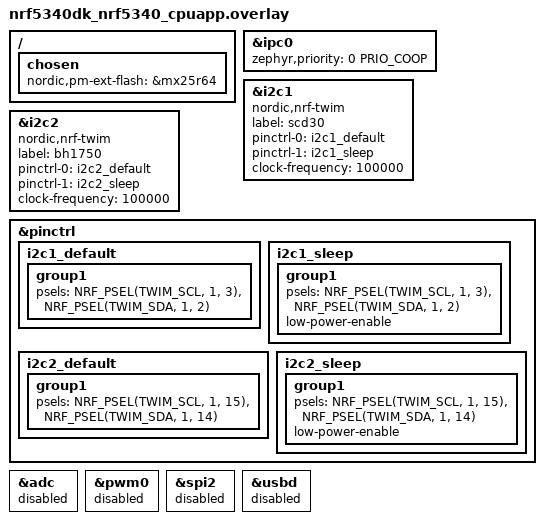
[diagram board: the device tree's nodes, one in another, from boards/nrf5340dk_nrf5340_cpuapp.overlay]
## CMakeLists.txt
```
#
# Copyright (c) 2021 Nordic Semiconductor ASA
#
# SPDX-License-Identifier: LicenseRef-Nordic-5-Clause
#

cmake_minimum_required(VERSION 3.20.0)

get_filename_component(MATTER_MODULE_ROOT $ENV{ZEPHYR_BASE}/../modules/lib/matter REALPATH)

# Set Kconfig root files that will be processed as a first Kconfig for used child images.
set(mcuboot_KCONFIG_ROOT ${MATTER_MODULE_ROOT}/config/nrfconnect/chip-module/Kconfig.mcuboot.root)
set(multiprotocol_rpmsg_KCONFIG_ROOT ${MATTER_MODULE_ROOT}/config/nrfconnect/chip-module/Kconfig.multiprotocol_rpmsg.root)
set(hci_rpmsg_KCONFIG_ROOT ${MATTER_MODULE_ROOT}/config/nrfconnect/chip-module/Kconfig.hci_rpmsg.root)

# For prj.conf the CONF_FILE is empty. In other case extract the exact file name from the path string.
if(CONF_FILE)
    get_filename_component(CONFIG_FILE_NAME ${CONF_FILE} NAME)
endif()

if(NOT CONFIG_FILE_NAME STREQUAL "prj_no_dfu.conf")
    set(PM_STATIC_YML_FILE ${CMAKE_CURRENT_SOURCE_DIR}/configuration/${BOARD}/pm_static_dfu.yml)
endif()

find_package(Zephyr HINTS $ENV{ZEPHYR_BASE})

project(matter-nrf-sensor-test)

set(COMMON_ROOT ${ZEPHYR_NRF_MODULE_DIR}/samples/matter/common)
set(NLIO_ROOT ${MATTER_MODULE_ROOT}/third_party/nlio/repo)
include(${MATTER_MODULE_ROOT}/config/nrfconnect/app/enable-gnu-std.cmake)
include(${MATTER_MODULE_ROOT}/src/app/chip_data_model.cmake)

# NORDIC SDK APP START
target_include_directories(app PRIVATE
    src
    ${COMMON_ROOT}/src
    ${NLIO_ROOT}/include
    ${MATTER_MODULE_ROOT}/zzz_generated/app-common
)

target_sources(app PRIVATE
    src/app_task.cpp
    src/app_driver.cpp
    src/main.cpp
    src/zcl_callbacks.cpp
    src/zap-generated/IMClusterCommandHandler.cpp
    src/zap-generated/callback-stub.cpp
    ${COMMON_ROOT}/src/led_widget.cpp
    $<$<BOOL:${CONFIG_NET_L2_OPENTHREAD}>:${COMMON_ROOT}/src/thread_util.cpp>
)

if(CONFIG_CHIP_OTA_REQUESTOR)
    target_sources(app PRIVATE ${COMMON_ROOT}/src/ota_util.cpp)
endif()

chip_configure_data_model(app
    INCLUDE_SERVER
    ZAP_FILE ${CMAKE_CURRENT_SOURCE_DIR}/src/template.zap
)
# NORDIC SDK APP END
```

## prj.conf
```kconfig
#
# Copyright (c) 2021 Nordic Semiconductor ASA
#
# SPDX-License-Identifier: LicenseRef-Nordic-5-Clause
#

# This sample uses Kconfig.defaults to set options common for all
# samples. This file should contain only options specific for this sample
# or overrides of default values.

# Enable CHIP
CONFIG_CHIP=y
CONFIG_CHIP_ENABLE_PAIRING_AUTOSTART=y
CONFIG_CHIP_PROJECT_CONFIG="src/chip_project_config.h"
# 32768 == 0x8000 (example Product ID added temporaly,
# but it must be changed with proper PID from the list:
# https://github.com/project-chip/connectedhomeip/blob/482e6fd03196a6de45465a90003947ef4b86e0b1/docs/examples/discussion/PID_allocation_for_example_apps.md)
CONFIG_CHIP_DEVICE_PRODUCT_ID=32768
CONFIG_STD_CPP14=y

# Add support for LEDs and buttons on Nordic development kits
CONFIG_DK_LIBRARY=y

# Bluetooth Low Energy configuration
CONFIG_BT_DEVICE_NAME="MatterTemplate"

# Other settings
CONFIG_THREAD_NAME=y
CONFIG_MPU_STACK_GUARD=y
CONFIG_RESET_ON_FATAL_ERROR=n

# Disable NFC commissioning
CONFIG_CHIP_NFC_COMMISSIONING=n

CONFIG_GPIO=y

CONFIG_GPIO_GET_CONFIG=y

#CONFIG_MAIN_STACK_SIZE=4096

# Stacks and heaps
CONFIG_MAIN_STACK_SIZE=16384
CONFIG_HEAP_MEM_POOL_SIZE=16384

# I2C
CONFIG_I2C=y
CONFIG_NRFX_TWIM1=y


# Rebooot
CONFIG_REBOOT=n
CONFIG_RESET_ON_FATAL_ERROR=n
```

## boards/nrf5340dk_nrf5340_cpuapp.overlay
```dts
/*
 * Copyright (c) 2021 Nordic Semiconductor ASA
 *
 * SPDX-License-Identifier: LicenseRef-Nordic-5-Clause
 */

#include <zephyr/dt-bindings/ipc_service/static_vrings.h>

/ {
	chosen {
		nordic,pm-ext-flash = &mx25r64;
	};
};

&ipc0 {
    zephyr,priority = <0 PRIO_COOP>;
};
&i2c1 {
	status = "okay";
	compatible = "nordic,nrf-twim";
	label = "scd30";
	pinctrl-0 = <&i2c1_default>;
	pinctrl-1 = <&i2c1_sleep>;
	pinctrl-names = "default", "sleep";
	clock-frequency = <100000>; 
};

&i2c2 {
	status = "okay";
	compatible = "nordic,nrf-twim";
	label = "bh1750";
	pinctrl-0 = <&i2c2_default>;
	pinctrl-1 = <&i2c2_sleep>;
	pinctrl-names = "default", "sleep";
	clock-frequency = <100000>; 
};

&pinctrl {
	i2c1_default: i2c1_default{
		group1 {
			psels = <NRF_PSEL(TWIM_SCL, 1, 3)>,
				<NRF_PSEL(TWIM_SDA, 1, 2)>;
		};
	};

	i2c1_sleep: i2c1_sleep{
		group1 {
			psels = <NRF_PSEL(TWIM_SCL, 1, 3)>,
					<NRF_PSEL(TWIM_SDA, 1, 2)>;
			low-power-enable;
		};
	};
	
	i2c2_default: i2c2_default{
		group1 {
			psels = <NRF_PSEL(TWIM_SCL, 1, 15)>,
					<NRF_PSEL(TWIM_SDA, 1, 14)>;
		};
	};

	i2c2_sleep: i2c2_sleep{
		group1 {
			psels = <NRF_PSEL(TWIM_SCL, 1, 15)>,
					<NRF_PSEL(TWIM_SDA, 1, 14)>;
			low-power-enable;
		};
	};
};

/* Disable unused peripherals to reduce power consumption */
&adc {
	status = "disabled";
};
&pwm0 {
	status = "disabled";
};
&spi2 {
	status = "disabled";
};
&usbd {
	status = "disabled";
};
```

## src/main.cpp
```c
/*
 * Copyright (c) 2021 Nordic Semiconductor ASA
 *
 * SPDX-License-Identifier: LicenseRef-Nordic-5-Clause
 */

#include "app_task.h"

#include <zephyr/logging/log.h>


int main()
{
	CHIP_ERROR err = AppTask::Instance().StartApp();

	LOG_ERR("Exited with code %" CHIP_ERROR_FORMAT, err.Format());
	return err == CHIP_NO_ERROR ? EXIT_SUCCESS : EXIT_FAILURE;
}
```

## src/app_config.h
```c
/*
 * Copyright (c) 2022 Nordic Semiconductor ASA
 *
 * SPDX-License-Identifier: LicenseRef-Nordic-5-Clause
 */

#pragma once

/* ---- Template App Config ---- */

#include "board_util.h"

#include <zephyr/kernel.h>
#include <zephyr/drivers/gpio.h>

#define LIGHTING_BUTTON DK_BTN1
#define LIGHTING_BUTTON_MASK DK_BTN1_MSK

#define SYSTEM_STATE_LED DK_LED2
//#define FACTORY_RESET_SIGNAL_LED DK_LED2

/* The devicetree node identifier for the "led0" alias. */
#define LED0_NODE DT_ALIAS(led0)


static constexpr struct gpio_dt_spec led = GPIO_DT_SPEC_GET(LED0_NODE, gpios);
```

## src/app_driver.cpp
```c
/**
 * @file app_driver.cpp
 * @author your name (you@domain.com)
 * @brief 
 * @version 0.1
 * @date 2023-02-24
 * 
 * @copyright Copyright (c) 2021, Sensirion AG
 * Copyright (c) 2021 Ruslan V. Uss <unclerus@gmail.com>
 * Copyright (c) 2021 Nate Usher <n.usher87@gmail.com>
 * 
 * Redistribution and use in source and binary forms, with or without
 * modification, are permitted provided that the following conditions are met:
 *
 * 1. Redistributions of source code must retain the above copyright notice,
 *    this list of conditions and the following disclaimer.
 * 2. Redistributions in binary form must reproduce the above copyright notice,
 *    this list of conditions and the following disclaimer in the documentation
 *    and/or other materials provided with the distribution.
 * 3. Neither the name of the copyright holder nor the names of itscontributors
 *    may be used to endorse or promote products derived from this software without
 *    specific prior written permission.
 *
 * THIS SOFTWARE IS PROVIDED BY THE COPYRIGHT HOLDERS AND CONTRIBUTORS "AS IS"
 * AND ANY EXPRESS OR IMPLIED WARRANTIES, INCLUDING, BUT NOT LIMITED TO, THE
 * IMPLIED WARRANTIES OF MERCHANTABILITY AND FITNESS FOR A PARTICULAR PURPOSE ARE
 * DISCLAIMED. IN NO EVENT SHALL THE COPYRIGHT HOLDER OR CONTRIBUTORS BE LIABLE
 * FOR ANY DIRECT, INDIRECT, INCIDENTAL, SPECIAL, EXEMPLARY, OR CONSEQUENTIAL
 * DAMAGES (INCLUDING, BUT NOT LIMITED TO, PROCUREMENT OF SUBSTITUTE GOODS OR
 * SERVICES; LOSS OF USE, DATA, OR PROFITS; OR BUSINESS INTERRUPTION) HOWEVER
 * CAUSED AND ON ANY THEORY OF LIABILITY, WHETHER IN CONTRACT, STRICT LIABILITY,
 * OR TORT (INCLUDING NEGLIGENCE OR OTHERWISE) ARISING IN ANY WAY OUT OF THE USE
 * OF THIS SOFTWARE, EVEN IF ADVISED OF THE POSSIBILITY OF SUCH DAMAGE.
 */

#include "app_driver.h"

#include <zephyr/kernel.h>
#include <zephyr/drivers/i2c.h>
#include <zephyr/device.h>
#include <zephyr/logging/log.h>

/**
 * @brief BH1750 I2C Device driver class. Suitable for reading lux values when requested. 
 * 
 * @param name I2C device name, as listed in i2c board overlay
 */
BH1750Driver::BH1750Driver(const std::string name)
    : spec{
        .bus = device_get_binding(name.c_str()), 
        .addr = I2C_ADDR
    }
{   
    // Get I2C device
    if (spec.bus == NULL)
    {
        LOG_ERR("Failed to get I2C device");
    } else
    {
        LOG_INF("Binded to device %s", spec.bus->name);
    }

    if (spec.addr != I2C_ADDR) {
        LOG_ERR("Address not set properly");
    }

    LOG_INF("[BH1750] Bus name: %s. Device addr: %d", spec.bus->name, spec.addr);
}

/**
 * @brief Initialize and configure i2c device. Set I2C speed to standard and write an initialization command
 * 
 * @param init_command (uint8_t *) 
 * @param buf_size 
 * 
 * @retval 0 If successful.
 * @retval -EIO General input / output error.
 */
int BH1750Driver::init()
{

    i2c_configure(spec.bus, I2C_SPEED_SET(I2C_SPEED_STANDARD));
    LOG_INF("Value of NRF_TWIM2_->PSEL.SCL : %d",NRF_TWIM2->PSEL.SCL);
    LOG_INF("Value of NRF_TWIM2->PSEL.SDA : %d",NRF_TWIM2->PSEL.SDA);
    LOG_INF("Value of NRF_TWIM2->FREQUENCY: %d",NRF_TWIM2->FREQUENCY);
    LOG_INF("26738688 -> 100k");

    uint8_t init_command[] = { CMD_TRIGGER_MEASUREMENT_MODE };

    CHECK(i2c_write_dt(&spec, init_command, 1), "I2C: Error in i2c_write transfer");
    return 0;
}

/**
 * @brief Read a value from the BH1750 device, convert to lux, and return.
 * 
 * @param lux (uint16_t *) [out] 
 * 
 * @retval 0 If successful.
 * @retval -EIO General input / output error.
 */
int BH1750Driver::read(uint16_t * lux) 
{
    const uint32_t num_bytes = 2;
    uint8_t value[2];

    CHECK(i2c_read_dt(&spec, value, num_bytes), 
        "I2C: Error in i2c_read transfer");

    *lux = ((value[0] << 8) | value[1]) / CONV_FACTOR;

    return 0;
}

/**
 * @brief Construct a new SCD30Driver object. Set I2C speed to standard and bind to I2C device
 * 
 * @param name (std::string) Name in board overlay i2c definition
 */
SCD30Driver::SCD30Driver(const std::string name)
    : spec{
        .bus = device_get_binding(name.c_str()), 
        .addr = I2C_ADDR
    }
{
    // Get I2C device
    if (spec.bus == NULL)
    {
        LOG_ERR("Failed to get I2C device");
    } else
    {
        LOG_INF("Binded to device %s", spec.bus->name);
    }

    if (spec.addr != I2C_ADDR) {
        LOG_ERR("Address not set properly");
    }

    LOG_INF("[SCD30] Bus name: %s. Device addr: %d", spec.bus->name, spec.addr);
}

/**
 * @brief Initialization SCD30 device. Read firmware version, and trigger continuous measurement mode.
 * 
 * @retval 0 If successful.
 * @retval -EIO General input / output error.
 */
int SCD30Driver::init()
{
    uint16_t version;

    i2c_configure(spec.bus, I2C_SPEED_SET(I2C_SPEED));
    LOG_INF("Value of NRF_TWIM1_->PSEL.SCL : %d ",NRF_TWIM1->PSEL.SCL);
    LOG_INF("Value of NRF_TWIM1->PSEL.SDA : %d ",NRF_TWIM1->PSEL.SDA);
    LOG_INF("Value of NRF_TWIM1->FREQUENCY: %d ",NRF_TWIM1->FREQUENCY);
    LOG_INF("26738688 -> 100k");

    CHECK(read_firmware_version(&version), "Error reading firmware version");

    LOG_INF("SCD30 Firmware Version: %d.%d", (version >> 8) & 0xf, version & 0xf);

    LOG_INF("Starting continuous measurement");
    
    CHECK(trigger_continuous_measurement(0), "Could not start continuous measurement");

    k_sleep(K_MSEC(2000));

    return 0;
}

/**
 * @brief Read the firmware version from SCD30 device
 * 
 * @param firmware_version (uint16_t *) [out] First byte holds major firmware version, second byte hold minor firmware version
 * 
 * @retval 0 If successful.
 * @retval -EIO General input / output error.
 */
int SCD30Driver::read_firmware_version(uint16_t *firmware_version)
{
    CHECK(execute_cmd(CMD_READ_FIRMWARE_VERSION, 8, NULL, 0, firmware_version, 1), 
        "Could not read firware version");
    return 0;
}

/**
 * @brief Sends command to SCD30 device to trigger continuous mesasurement. 
 * 
 * @param p_comp (uint16_t) TODO: Figure out what this param is 
 * 
 * @retval 0 If successful.
 * @retval -EIO General input / output error.
 */
int SCD30Driver::trigger_continuous_measurement(uint16_t p_comp)
{
    CHECK(p_comp != 0 && (p_comp < 700 || p_comp > 1400), "p_comp invalid"); 
    
    CHECK(execute_cmd(CMD_TRIGGER_CONTINUOUS_MEASUREMENT, 8, &p_comp, 1, NULL, 0), 
        "Could not trigger continuous measurements");
    return 0;
}

/**
 * @brief Can be used to check if the SCD30 data is ready to be read
 * 
 * @param data_ready [out] True if data is ready, false if it is not
 * 
 * @retval 0 If successful.
 * @retval -EIO General input / output error.
 */
int SCD30Driver::get_data_ready_status(bool * data_ready)
{
    uint16_t status;
    
    CHECK(execute_cmd(CMD_GET_DATA_READY_STATUS, 8, NULL, 0, &status, 1), 
        "Failed to check if data is ready");

    *data_ready = (status != 0);
    if (*data_ready)
    {
        LOG_INF("Data ready...");
    } else 
    {
        LOG_ERR("Data not ready | status: %u", status);
    }
    return 0;
}

/**
 * @brief Read the co2, temperature and humidity readings from the SCD30 device. 
 * 
 * @param co2 (float *) Pointer to the co2 reading in ppm
 * @param temperature (float *) Pointer the temperature reading in degrees celsius
 * @param humidity (float *) Pointer to the relative humidity reading in percent
 * 
 * @retval 0 If successful.
 * @retval -EIO General input / output error.
 */
int SCD30Driver::read_measurement(float * co2, float * temperature, float * humidity)
{
    static constexpr size_t BUF_WORDS = 6U;
    static constexpr uint16_t SLEEP_TIME_MS = 8U;
    uint16_t buf[BUF_WORDS];

    union {
        uint32_t u32;
        float f;
    } tmp;

    CHECK(execute_cmd(CMD_READ_MEASUREMENT, SLEEP_TIME_MS, NULL, 0U, buf, BUF_WORDS), 
        "Failed to send read measurement command");
    
    if (co2)
    {
        tmp.u32 = ((uint32_t)buf[0] << 16) | buf[1];
        *co2 = tmp.f;
    }
    if (temperature)
    {
        tmp.u32 = ((uint32_t)buf[2] << 16) | buf[3];
        *temperature = tmp.f;
    }
    if (humidity)
    {
        tmp.u32 = ((uint32_t)buf[4] << 16) | buf[5];
        *humidity = tmp.f;
    }

    return 0;
}

/**
 * @brief Execute a cmd on the SCD30 device, and recieve the reponse. 
 * 
 * @param cmd (uint16_t) Command to send the device, as defined in the SCD30 documentation
 * @param timeout_ms (uint32_t) Timoeut in ms betweeen sending a command and recieveing the resopnse. For reading data it should be at least 3MS
 * @param in_data (uint16_t *) Any arguments to be sent to the device, along with the command  
 * @param in_words (size_t) Size of input data in words
 * @param out_data (uint16_t *) Data returned by by device
 * @param out_words (size_t) Size of output data in words
 * 
 * @retval 0 If successful.
 * @retval -EIO General input / output error.
 */
int SCD30Driver::execute_cmd(const uint16_t cmd, uint32_t timeout_ms,
        uint16_t *in_data, size_t in_words, uint16_t *out_data, size_t out_words)
{
    CHECK(send_cmd(cmd, in_data, in_words), "Failed to send cmd in execute_cmd");

    k_sleep(K_MSEC(timeout_ms));

    if (out_data && out_words)
    {
        CHECK(read_resp(out_data, out_words), "Failed to read response in execute_cmd");
    }

    return 0;
}

/**
 * @brief Send a command to SCD30, optionally with arguments.
 * 
 * @param cmd Two byte command to send (byte order is swapped)
 * @param data Any additional argument data
 * @param words 
 * @return int 
 */
int SCD30Driver::send_cmd(uint16_t cmd, uint16_t *data, size_t words)
{
    uint8_t buf[2 + words * 3];
    *(uint16_t *)buf = swap(cmd);
    
    if(data != NULL && words > 0)
    {
        for (size_t i = 0; i < words; i++)
        {
            uint8_t *p = buf + 2 + i * 3;
            *(uint16_t *)p = swap(data[i]);
            *(p + 2) = crc8(p, 2);
        }
    }

    LOG_INF("Sending buffer...");

    CHECK(i2c_write_dt(&spec, buf, sizeof(buf)),
        "Could not write command via I2C");
    
    return 0;
}

/**
 * @brief Read the result of a previously sent commmand. Uses crc8 checksum to check the result. 
 * 
 * @param data (uint16_t *) [out] Buffer to put data in
 * @param words (size_t) Number of words to read from buffer
 * 
 * @retval 0 If successful.
 * @retval -EIO General input / output error.
 */
int SCD30Driver::read_resp(uint16_t *data, size_t words)
{
    uint8_t buf[words * 3];
    
    CHECK(i2c_read_dt(&spec, buf, sizeof(buf)), "Could not response to buffer");

    LOG_INF("Received buffer...");

    for (size_t i = 0; i < words; i++)
    {
        uint8_t *p = buf + i * 3;
        uint8_t crc = crc8(p, 2);
        
        CHECK(crc != *(p + 2), "Invalid CRC");

        data[i] = swap(*(uint16_t *)p);
    }
    return 0;
}

/**
 * @brief Compute crc8 checksum for a give set of bytes and return the result
 * 
 * @param data (uint8_t *) Data to use for checksum
 * @param count (size_t) Number of bytes for data
 * @return (uint8_t) 8 bit checksum
 */
uint8_t SCD30Driver::crc8(const uint8_t * data, size_t count)
{
    uint8_t res = 0xff;

    for (size_t i = 0; i < count; ++i)
    {
        res ^= data[i];
        for (uint8_t bit = 8; bit > 0; --bit)
        {
            if (res & 0x80)
                res = (res << 1) ^ 0x31;
            else
                res = (res << 1);
        }
    }
    return res;
}

/**
 * @brief Swap first and last bytes of word
 * 
 * @param v (uint16) Word to swap
 * @return (uint16_t) Swapped word
 */
inline uint16_t SCD30Driver::swap(uint16_t v)
{
    return (v << 8) | (v >> 8);
}
```

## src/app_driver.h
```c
#pragma once

#include <string>
#include <zephyr/drivers/i2c.h>
#include <zephyr/logging/log.h>

#ifndef CHECK
#define CHECK(x, ...) ({ \
    int __ = x; \
    if (__) { \
        LOG_ERR(__VA_ARGS__" ERROR #%d", x); \
        return __; \
    } \
})
#endif

#ifndef CHECK_RET_VOID
#define CHECK_RET_VOID(x, ...) ({ \
    int __ = x; \
    if (__) { \
        LOG_ERR(__VA_ARGS__" ERROR #%d", x); \
        return; \
    } \
})
#endif

#ifndef LOGGING_MODULE_DECLARATION
#define LOGGING_MODULE_DECLARATION
LOG_MODULE_DECLARE(app, CONFIG_MATTER_LOG_LEVEL);
#endif

class BH1750Driver
{
public:
    BH1750Driver (const std::string name);

    int init();
    int read(uint16_t * lux);
private:
    const struct i2c_dt_spec spec;

    static constexpr uint16_t I2C_ADDR=0x23;
    static constexpr uint8_t CMD_TRIGGER_MEASUREMENT_MODE=0x10;
    static constexpr float CONV_FACTOR = 1.2;
};


class SCD30Driver
{
public:
    SCD30Driver (const std::string name);

    int init();
    int get_data_ready_status(bool * data_ready);
    int read_measurement(float *co2, float *temperature, float *humidity);
private:
    uint8_t crc8(const uint8_t *data, size_t count);
    inline uint16_t swap(uint16_t v);
    int send_cmd(uint16_t cmd, uint16_t *data, size_t words);
    int read_resp(uint16_t *data, size_t words);
    int execute_cmd(const uint16_t cmd, uint32_t timeout_ms,
                             uint16_t *out_data, size_t out_words, uint16_t *in_data, size_t in_words);
    int read_firmware_version(uint16_t *firmware_version);
    int trigger_continuous_measurement(uint16_t p_comp);

    const struct i2c_dt_spec spec;

    static constexpr uint16_t I2C_ADDR=0x61;
 
    static constexpr uint16_t CMD_TRIGGER_CONTINUOUS_MEASUREMENT=0x0010; 
    static constexpr uint16_t CMD_STOP_CONTINUOUS_MEASUREMENT=0x0104;
    static constexpr uint16_t CMD_SET_MEASUREMENT_uint16_tERVAL=0x4600;
    static constexpr uint16_t CMD_GET_DATA_READY_STATUS=0x0202;
    static constexpr uint16_t CMD_READ_MEASUREMENT=0x0300;
    static constexpr uint16_t CMD_ACTIVATE_AUTOMATIC_SELF_CALIBRATION=0x5306;
    static constexpr uint16_t CMD_SET_FORCED_RECALIBRATION_VALUE=0x5204;
    static constexpr uint16_t CMD_SET_TEMPERATURE_OFFSET=0x5403;
    static constexpr uint16_t CMD_ALTITUDE_COMPENSATION=0x5102;
    static constexpr uint16_t CMD_READ_FIRMWARE_VERSION=0xD100;
    static constexpr uint16_t CMD_SOFT_RESET=0xD304;

    static constexpr uint32_t I2C_SPEED = I2C_SPEED_STANDARD;
};
```

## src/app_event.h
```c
/*
 * Copyright (c) 2021 Nordic Semiconductor ASA
 *
 * SPDX-License-Identifier: LicenseRef-Nordic-5-Clause
 */

#pragma once

#include <cstdint>

#include "event_types.h"

class LEDWidget;

enum class AppEventType : uint8_t { 
	None = 0, 
	SensorFetch,
	Lighting
};

enum class AppEventEndpointID: uint8_t {
	None = 0,
	Temperature = 1,
	RelativeHumidity = 2,
	Illuminance = 3,
	Light = 4
};

struct AppEvent {
	union {
		struct {
			void *Context;
		} TimerEvent;
	};

	AppEventType Type{ AppEventType::None };
	AppEventEndpointID Cluster{ AppEventEndpointID::None };
	EventHandler Handler;
};
```

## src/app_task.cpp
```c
/*
 * Copyright (c) 2021 Nordic Semiconductor ASA
 *
 * SPDX-License-Identifier: LicenseRef-Nordic-5-Clause
 */

#include "app_task.h"
#include "app_config.h"
#include "led_util.h"
#include "app_driver.h"

#include "thread_util.h"

#include <platform/CHIPDeviceLayer.h>
#include <zephyr/drivers/gpio.h>

#include "board_util.h"
#include <app-common/zap-generated/attributes/Accessors.h>
#include <app/server/OnboardingCodesUtil.h>
#include <app/server/Server.h>
#include <credentials/DeviceAttestationCredsProvider.h>
#include <credentials/examples/DeviceAttestationCredsExample.h>
#include <lib/support/CHIPMem.h>
#include <lib/support/CodeUtils.h>
#include <system/SystemError.h>

#include "ota_util.h"

#include <dk_buttons_and_leds.h>
#include <zephyr/logging/log.h>
#include <zephyr/kernel.h>

#include <zephyr/kernel.h>
#include <zephyr/drivers/gpio.h>

using namespace ::chip;
using namespace ::chip::app;
using namespace ::chip::Credentials;
using namespace ::chip::DeviceLayer;

namespace
{
	constexpr size_t kAppEventQueueSize = 10;

	K_MSGQ_DEFINE(sAppEventQueue, sizeof(AppEvent), kAppEventQueueSize, alignof(AppEvent));

	bool sIsNetworkProvisioned = false;
	bool sIsNetworkEnabled = false;
	bool sHaveBLEConnections = false;

	BH1750Driver bh1750_driver("bh1750");
	SCD30Driver scd30_driver("scd30");

} /* namespace */

namespace Timers 
{
	k_timer sSCD30Sensor;
	k_timer sBH1750Sensor;

	namespace FetchPeriodSeconds 
	{
		constexpr uint32_t sSCD30Sensor{ 20 };
		constexpr uint32_t sBH1750Sensor{ 2 };
	} /* FetchPeriodSeconds */
} /* Timers */

/**
 * @brief Initialize chip stack
 * 
 * @return CHIP_ERROR 
 */
CHIP_ERROR AppTask::Init()
{
	/* Initialize CHIP stack */
	LOG_INF("Init CHIP stack");

	CHIP_ERROR err = chip::Platform::MemoryInit();

	if (err != CHIP_NO_ERROR) 
	{
		LOG_ERR("Platform::MemoryInit() failed");
		return err;
	}

	err = PlatformMgr().InitChipStack();
	if (err != CHIP_NO_ERROR) {
		LOG_ERR("PlatformMgr().InitChipStack() failed");
		return err;
	}

	err = ThreadStackMgr().InitThreadStack();
	if (err != CHIP_NO_ERROR) {
		LOG_ERR("ThreadStackMgr().InitThreadStack() failed: %s", ErrorStr(err));
		return err;
	}

	err = ConnectivityMgr().SetThreadDeviceType(ConnectivityManager::kThreadDeviceType_MinimalEndDevice);

	if (err != CHIP_NO_ERROR) {
		LOG_ERR("ConnectivityMgr().SetThreadDeviceType() failed: %s", ErrorStr(err));
		return err;
	}

	if(bh1750_driver.init()) {
		LOG_ERR("Error in BH1750 init");
		return CHIP_ERROR_NOT_CONNECTED;
	}

	if(scd30_driver.init()) {
		LOG_ERR("Error in SCD30 init");
		return CHIP_ERROR_NOT_CONNECTED;
	}


	/* Initialize sensor timers */
	k_timer_init(&Timers::sSCD30Sensor, &AppTask::SCD30MeasurementTimeoutCallback, nullptr);
	k_timer_user_data_set(&Timers::sSCD30Sensor, this);
	k_timer_start(&Timers::sSCD30Sensor, K_NO_WAIT, K_SECONDS(Timers::FetchPeriodSeconds::sSCD30Sensor));

	k_timer_init(&Timers::sBH1750Sensor, &AppTask::BH1750MeasurementTimeoutCallback, nullptr);
	k_timer_user_data_set(&Timers::sBH1750Sensor, this);
	k_timer_start(&Timers::sBH1750Sensor, K_NO_WAIT, K_SECONDS(Timers::FetchPeriodSeconds::sBH1750Sensor));

	SetDeviceAttestationCredentialsProvider(Examples::GetExampleDACProvider());

	static chip::CommonCaseDeviceServerInitParams initParams;
	(void)initParams.InitializeStaticResourcesBeforeServerInit();

	ReturnErrorOnFailure(chip::Server::GetInstance().Init(initParams));
	ConfigurationMgr().LogDeviceConfig();

	//QR code is currently wrong it appears, so avoid printing for now
	//TODO: Figure out how to print proper QR Code
	//PrintOnboardingCodes(chip::RendezvousInformationFlags(chip::RendezvousInformationFlag::kBLE));

	/*
	 * Add CHIP event handler and start CHIP thread.
	 * Note that all the initialization code should happen prior to this point to avoid data races
	 * between the main and the CHIP threads.
	 */
	PlatformMgr().AddEventHandler(ChipEventHandler, 0);

	err = PlatformMgr().StartEventLoopTask();
	if (err != CHIP_NO_ERROR) {
		LOG_ERR("PlatformMgr().StartEventLoopTask() failed");
		return err;
	}

	return CHIP_NO_ERROR;
}

/**
 * @brief Call init and then get and dispatch message events in a loop
 * 
 * @return (CHIP_ERROR) Return any error value upon initialization. Otherwise it should not return.
 */
CHIP_ERROR AppTask::StartApp()
{
	ReturnErrorOnFailure(Init());

	AppEvent event = {};

	while (true)
	{
		k_msgq_get(&sAppEventQueue, &event, K_FOREVER);
		DispatchEvent(event);
	}

	return CHIP_NO_ERROR;
}

/**
 * @brief Callback function for SCD30 timer timeout. Adds SCD30 sensor reading function to event queue
 * 
 * @param timer (k_timer *) Pointer to timer from which callback is called.
 */
void AppTask::SCD30MeasurementTimeoutCallback(k_timer * timer) 
{
	if (!timer) return;

	AppEvent event;
	event.Type = AppEventType::SensorFetch;
	event.TimerEvent.Context = k_timer_user_data_get(timer);
	event.Handler = FunctionSCD30FetchEventHandler;
	PostEvent(event);
}

/**
 * @brief Callback function for BH1750 timer timeout. Adds BH1750 sensor reading function to event queue
 * 
 * @param timer (k_timer *) Pointer to timer from which callback is called.
 */
void AppTask::BH1750MeasurementTimeoutCallback(k_timer * timer)
{
	if (!timer) return;

	AppEvent event;
	event.Type = AppEventType::SensorFetch;
	event.TimerEvent.Context = k_timer_user_data_get(timer);
	event.Handler = FunctionBH1750EventHandler;
	PostEvent(event);
}



/**
 * @brief Reads SCD30 co2, temperature, humidity, and update the corrresponding matter attribute. If the on/off led is on,
 * then the SCD30 co2 reading is placed in the illuminance attribute (matter does not currently support CO2 readings). 
 * 
 * @param event (const AppEvent &event) event type
 */
void AppTask::FunctionSCD30FetchEventHandler(const AppEvent &event)
{
	bool data_ready = false;
	float co2 = 0.0, temperature = 0.0, humidity = 0.0;

	CHECK_RET_VOID(scd30_driver.get_data_ready_status(&data_ready), "Could not check data ready status");

	if(data_ready)
	{
		CHECK_RET_VOID(scd30_driver.read_measurement(&co2, &temperature, &humidity), "Error reading sensor data");
        CHECK_RET_VOID(co2 == 0, "Invalid co2 sample detected, skipping attribute updates");

		LOG_INF("Setting temp to: %d and humidity to %d",static_cast<uint16_t>(temperature*100), static_cast<uint16_t>(humidity*100));

		/* Simulate sensor for now */
		chip::app::Clusters::TemperatureMeasurement::Attributes::MeasuredValue::Set(
			static_cast<chip::EndpointId>(AppEventEndpointID::Temperature), static_cast<uint16_t>(temperature*100.0));

		chip::app::Clusters::RelativeHumidityMeasurement::Attributes::MeasuredValue::Set(
			static_cast<chip::EndpointId>(AppEventEndpointID::RelativeHumidity), static_cast<uint16_t>(humidity*100.0));

		//Put co2 values in illuminance attribute if on/off light is on, otherwise lux will be used
		if(gpio_pin_get_dt(&led))
		{
			chip::app::Clusters::IlluminanceMeasurement::Attributes::MeasuredValue::Set(
				static_cast<chip::EndpointId>(AppEventEndpointID::Illuminance), co2);
		}
	}
}

/**
 * @brief Reads BH1750 lux value, and updates the corrresponding matter attribute. If the on/off led is on,
 * then the SCD30 co2 reading is placed in the illuminance attribute (matter does not currently support CO2 readings). 
 * 
 * @param event (const AppEvent &event) event type
 */
void AppTask::FunctionBH1750EventHandler(const AppEvent &event)
{
	uint16_t lux;

	//Putting SCD30 CO2 values in illuminance matter attribute instead if onoff light is on
	if(gpio_pin_get_dt(&led))
	{
		return;
	}

	CHECK_RET_VOID(bh1750_driver.read(&lux), "Error in i2c_read transfer");

	chip::app::Clusters::IlluminanceMeasurement::Attributes::MeasuredValue::Set(
		static_cast<chip::EndpointId>(AppEventEndpointID::Illuminance), lux);
}

/**
 * @brief Handle chip events such as a bluetooth adveritising change, or a thread state change.
 * 
 * @param event (const ChipDeviceEvent *event) Chip event type. Currently kCHIPoBLEAdvertisingChange, kDnssdPlatformInitialized,
 * kThreadStateChange are handled.
 */
void AppTask::ChipEventHandler(const ChipDeviceEvent *event, intptr_t /* arg */)
{
	switch (event->Type)
	{
		case DeviceEventType::kCHIPoBLEAdvertisingChange:
			sHaveBLEConnections = ConnectivityMgr().NumBLEConnections() != 0;
			break;

		case DeviceEventType::kDnssdPlatformInitialized:
			InitBasicOTARequestor();
			break;

		case DeviceEventType::kThreadStateChange:
			sIsNetworkProvisioned = ConnectivityMgr().IsThreadProvisioned();
			sIsNetworkEnabled = ConnectivityMgr().IsThreadEnabled();
			break;
			
		default:
			break;
	}
}

/**
 * @brief Post event in the message queue
 * 
 * @param event (const AppEvent &) Event handler
 */
void AppTask::PostEvent(const AppEvent & event)
{
	CHECK_RET_VOID(k_msgq_put(&sAppEventQueue, &event, K_NO_WAIT) != 0, 
		"Failed to post event to app task event queue");
}

/**
 * @brief Dispatch the event by passing the event to the event
 * 
 * @param event (const AppEvent &) Event handler
 */
void AppTask::DispatchEvent(const AppEvent & event)
{
	CHECK_RET_VOID(!(event.Handler), "Event received with no handler. Dropping event.");
	event.Handler(event);
}
```

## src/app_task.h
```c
/*
 * Copyright (c) 2021 Nordic Semiconductor ASA
 *
 * SPDX-License-Identifier: LicenseRef-Nordic-5-Clause
 */

#pragma once

#include "app_event.h"
#include "app_driver.h"

#include <platform/CHIPDeviceLayer.h>


#ifndef CHECK
#define CHECK(x, ...) ({ \
    int __ = x; \
    if (__) { \
        LOG_ERR("ERR #%d: %s", x, __VA_ARGS__); \
        return __; \
    } \
})
#endif

#ifndef CHECK_RET_VOID
#define CHECK_RET_VOID(x, ...) ({ \
    int __ = x; \
    if (__) { \
        LOG_ERR(__VA_ARGS__" ERROR #%d", x); \
        return; \
    } \
})
#endif

#ifndef LOGGING_MODULE_DECLARATION
#define LOGGING_MODULE_DECLARATION
LOG_MODULE_DECLARE(app, CONFIG_MATTER_LOG_LEVEL);
#endif

class AppTask {
public:
	static AppTask &Instance()
	{
		static AppTask sAppTask;
		return sAppTask;
	};

	CHIP_ERROR StartApp();
	static void PostEvent(const AppEvent &event);
private:
	CHIP_ERROR Init();
	static void DispatchEvent(const AppEvent &event);
	static void FunctionSCD30FetchEventHandler(const AppEvent &event);
	static void FunctionBH1750EventHandler(const AppEvent &event);
	static void SCD30MeasurementTimeoutCallback(k_timer *timer);
	static void BH1750MeasurementTimeoutCallback(k_timer * timer);
	static void ChipEventHandler(const chip::DeviceLayer::ChipDeviceEvent *event, intptr_t arg);
};
```

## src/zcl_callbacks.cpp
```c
#include "app_task.h"
#include "app_driver.h"
#include "app_config.h"

#include <app-common/zap-generated/attributes/Accessors.h>
#include <app-common/zap-generated/ids/Attributes.h>
#include <app-common/zap-generated/ids/Clusters.h>
#include <app/ConcreteAttributePath.h>

#include <zephyr/kernel.h>
#include <zephyr/drivers/gpio.h>

#include <zephyr/logging/log.h>

/* 1000 msec = 1 sec */
#define SLEEP_TIME_MS   1000


using namespace ::chip;
using namespace ::chip::app::Clusters;
using namespace ::chip::app::Clusters::OnOff;

/**
 * @brief 
 * 
 * @param attributePath 
 * @param type 
 * @param size 
 * @param value 
 */
void MatterPostAttributeChangeCallback(const chip::app::ConcreteAttributePath & attributePath, uint8_t type,
                                       uint16_t size, uint8_t * value)
{
    if (attributePath.mClusterId == OnOff::Id && attributePath.mAttributeId == OnOff::Attributes::OnOff::Id) {
        gpio_pin_set_dt(&led, *value);
        LOG_INF("MatterPostAttributechangeCallback GPIO setting value to: %d\n", *value);

        //Reset illuminance attribute value
        chip::app::Clusters::IlluminanceMeasurement::Attributes::MeasuredValue::Set(
				static_cast<chip::EndpointId>(AppEventEndpointID::Illuminance), 0);
    }
}


/** @brief OnOff Cluster Init
 *
 * This function is called when a specific cluster is initialized. It gives the
 * application an opportunity to take care of cluster initialization procedures.
 * It is called exactly once for each endpoint where cluster is present.
 *
 * @param endpoint   Ver.: always
 *
 * TODO Issue #3841
 * emberAfOnOffClusterInitCallback happens before the stack initialize the cluster
 * attributes to the default value.
 * The logic here expects something similar to the deprecated Plugins callback
 * emberAfPluginOnOffClusterServerPostInitCallback.
 *
 */
void emberAfOnOffClusterInitCallback(EndpointId endpoint)
{
	EmberAfStatus status;
	bool storedValue;

	/* Read storedValue on/off value */
	status = Attributes::OnOff::Get(endpoint, &storedValue);
	if (status == EMBER_ZCL_STATUS_SUCCESS) {
        int ret;

        if (!device_is_ready(led.port)) {
            return;
        }

        ret = gpio_pin_configure_dt(&led, GPIO_OUTPUT_INACTIVE | GPIO_INPUT);
        if (ret < 0) {
            return;
        }
        LOG_INF("Setting Test LED high\n");
	}
}
```
